# ESP32-S31 register map
Vendor: ESPRESSIF SYSTEMS (SHANGHAI) CO., LTD.; Series: ESP32 S-Series; File version: 1
CPU: RV32IMAFC r0p0, little endian, no MPU, FPU, 0 interrupt priority bits
Address unit: 32 bits
Registers are 32-bit, read-write, reset 0x0 unless marked. A register's access mark holds for its fields unless they carry their own. Offsets are from the block's base; [hi:lo] are bit positions; {n}, {i} and the like mark numbered series.

## TEE — TEE Peripheral
Base 0x20504000
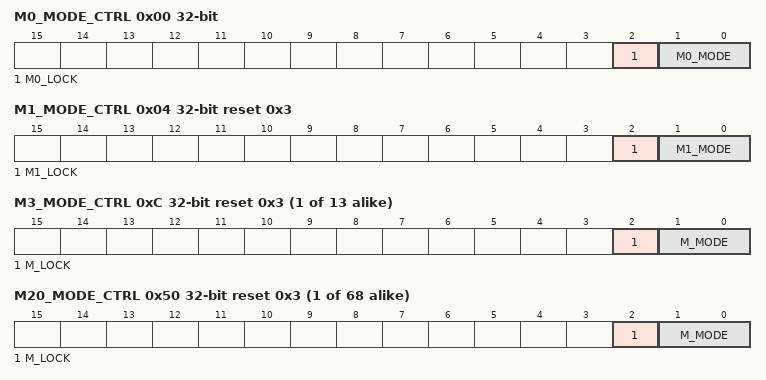
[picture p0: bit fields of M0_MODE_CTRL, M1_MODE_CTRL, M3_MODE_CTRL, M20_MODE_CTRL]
0x00 M0_MODE_CTRL — TEE mode control register
  [2] M0_LOCK — Set 1 to lock m0 tee configuration
  [1:0] M0_MODE — Configures M0 security level mode.\\ 0: tee_mode \\ 1: ree_mode0 \\ 2: ree_mode1 \\ 3: ree_mode2 \\
0x04 M1_MODE_CTRL reset 0x3 — TEE mode control register
  [2] M1_LOCK — Set 1 to lock m1 tee configuration
  [1:0] M1_MODE — Configures M0 security level mode.\\ 0: tee_mode \\ 1: ree_mode0 \\ 2: ree_mode1 \\ 3: ree_mode2 \\
{0x0+4i} M{i}_MODE_CTRL (i=3..15) reset 0x3 — TEE mode control register
  [2] M_LOCK — Set 1 to lock m3 tee configuration
  [1:0] M_MODE — Configures M%s security level mode.\\ 0: tee_mode \\ 1: ree_mode0 \\ 2: ree_mode1 \\ 3: ree_mode2 \\
{0x0+4i} M{i}_MODE_CTRL (i=20..87) reset 0x3 — TEE mode control register
  [2] M_LOCK — Set 1 to lock m20 tee configuration
  [1:0] M_MODE — Configures M%s security level mode.\\ 0: tee_mode \\ 1: ree_mode0 \\ 2: ree_mode1 \\ 3: ree_mode2 \\
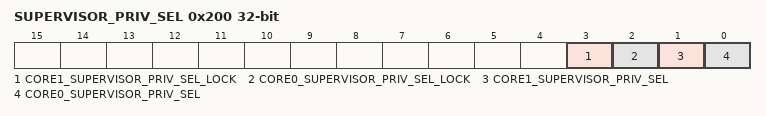
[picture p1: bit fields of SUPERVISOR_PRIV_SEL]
0x200 SUPERVISOR_PRIV_SEL — TEE mode control register
  [3] CORE1_SUPERVISOR_PRIV_SEL_LOCK — Set 1 to lock reg_core1_supervisor_priv_sel configuration
  [2] CORE0_SUPERVISOR_PRIV_SEL_LOCK — Set 1 to lock reg_core0_supervisor_priv_sel configuration
  [1] CORE1_SUPERVISOR_PRIV_SEL — Configures the privilege of the core0 supervisor mode .\\ 0: same as user_mode \\ 1: same as machine_mode \\
  [0] CORE0_SUPERVISOR_PRIV_SEL — Configures the privilege of the core0 supervisor mode .\\ 0: same as user_mode \\ 1: same as machine_mode \\
0x3F8 CLOCK_GATE reset 0x1 — Clock gating register
  [0] CLK_EN — Configures whether to keep the clock always on.\\ 0: enable automatic clock gating \\ 1: keep the clock always on \\
0x3FC DATE reset 0x2506250 — Version control register
  [27:0] DATE

## LP_TOUCH — LP_TOUCH Peripheral
Base 0x20816000
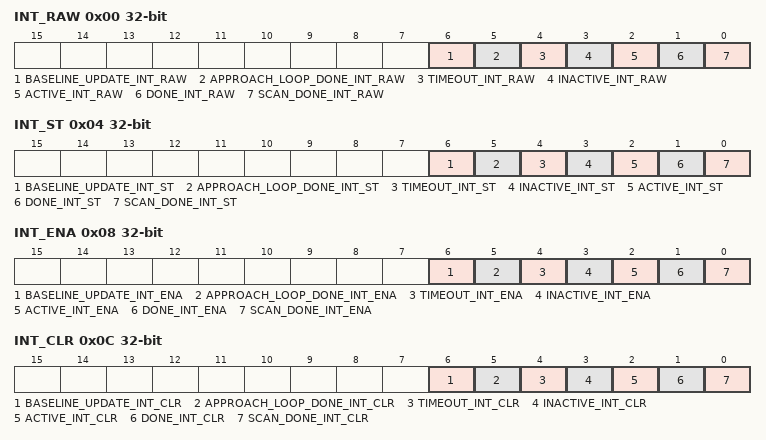
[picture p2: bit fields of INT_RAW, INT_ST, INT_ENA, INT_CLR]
0x00 INT_RAW — need_des
  [6] BASELINE_UPDATE_INT_RAW — need_des
  [5] APPROACH_LOOP_DONE_INT_RAW — need_des
  [4] TIMEOUT_INT_RAW — need_des
  [3] INACTIVE_INT_RAW — need_des
  [2] ACTIVE_INT_RAW — need_des
  [1] DONE_INT_RAW — need_des
  [0] SCAN_DONE_INT_RAW — need_des
0x04 INT_ST ro — need_des
  [6] BASELINE_UPDATE_INT_ST — need_des
  [5] APPROACH_LOOP_DONE_INT_ST — need_des
  [4] TIMEOUT_INT_ST — need_des
  [3] INACTIVE_INT_ST — need_des
  [2] ACTIVE_INT_ST — need_des
  [1] DONE_INT_ST — need_des
  [0] SCAN_DONE_INT_ST — need_des
0x08 INT_ENA — need_des
  [6] BASELINE_UPDATE_INT_ENA — need_des
  [5] APPROACH_LOOP_DONE_INT_ENA — need_des
  [4] TIMEOUT_INT_ENA — need_des
  [3] INACTIVE_INT_ENA — need_des
  [2] ACTIVE_INT_ENA — need_des
  [1] DONE_INT_ENA — need_des
  [0] SCAN_DONE_INT_ENA — need_des
0x0C INT_CLR wo — need_des
  [6] BASELINE_UPDATE_INT_CLR — need_des
  [5] APPROACH_LOOP_DONE_INT_CLR — need_des
  [4] TIMEOUT_INT_CLR — need_des
  [3] INACTIVE_INT_CLR — need_des
  [2] ACTIVE_INT_CLR — need_des
  [1] DONE_INT_CLR — need_des
  [0] SCAN_DONE_INT_CLR — need_des
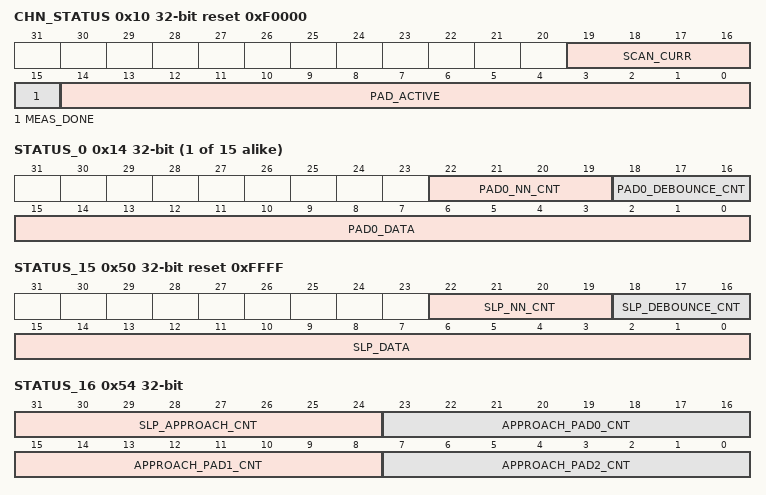
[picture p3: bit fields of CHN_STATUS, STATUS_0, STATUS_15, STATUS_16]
0x10 CHN_STATUS ro reset 0xF0000 — need_des
  [19:16] SCAN_CURR — need_des
  [15] MEAS_DONE — need_des
  [14:0] PAD_ACTIVE — need_des
{0x14+4i} STATUS_{i} ro (i=0..14) — need_des
  [22:19] PAD{i}_NN_CNT — need_des
  [18:16] PAD{i}_DEBOUNCE_CNT — need_des
  [15:0] PAD{i}_DATA — need_des
0x50 STATUS_15 ro reset 0xFFFF — need_des
  [22:19] SLP_NN_CNT — need_des
  [18:16] SLP_DEBOUNCE_CNT — need_des
  [15:0] SLP_DATA — need_des
0x54 STATUS_16 ro — need_des
  [31:24] SLP_APPROACH_CNT — need_des
  [23:16] APPROACH_PAD0_CNT — need_des
  [15:8] APPROACH_PAD1_CNT — need_des
  [7:0] APPROACH_PAD2_CNT — need_des
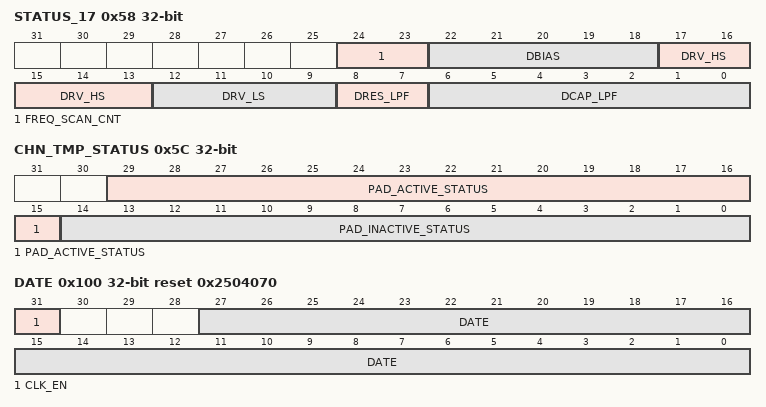
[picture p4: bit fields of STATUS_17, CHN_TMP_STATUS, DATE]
0x58 STATUS_17 ro — need_des
  [24:23] FREQ_SCAN_CNT — need_des
  [22:18] DBIAS — need_des
  [17:13] DRV_HS — need_des
  [12:9] DRV_LS — need_des
  [8:7] DRES_LPF — need_des
  [6:0] DCAP_LPF — Reserved
0x5C CHN_TMP_STATUS ro — need_des
  [29:15] PAD_ACTIVE_STATUS — need_des
  [14:0] PAD_INACTIVE_STATUS — need_des
0x100 DATE reset 0x2504070 — need_des
  [31] CLK_EN — need_des
  [27:0] DATE — need_des
